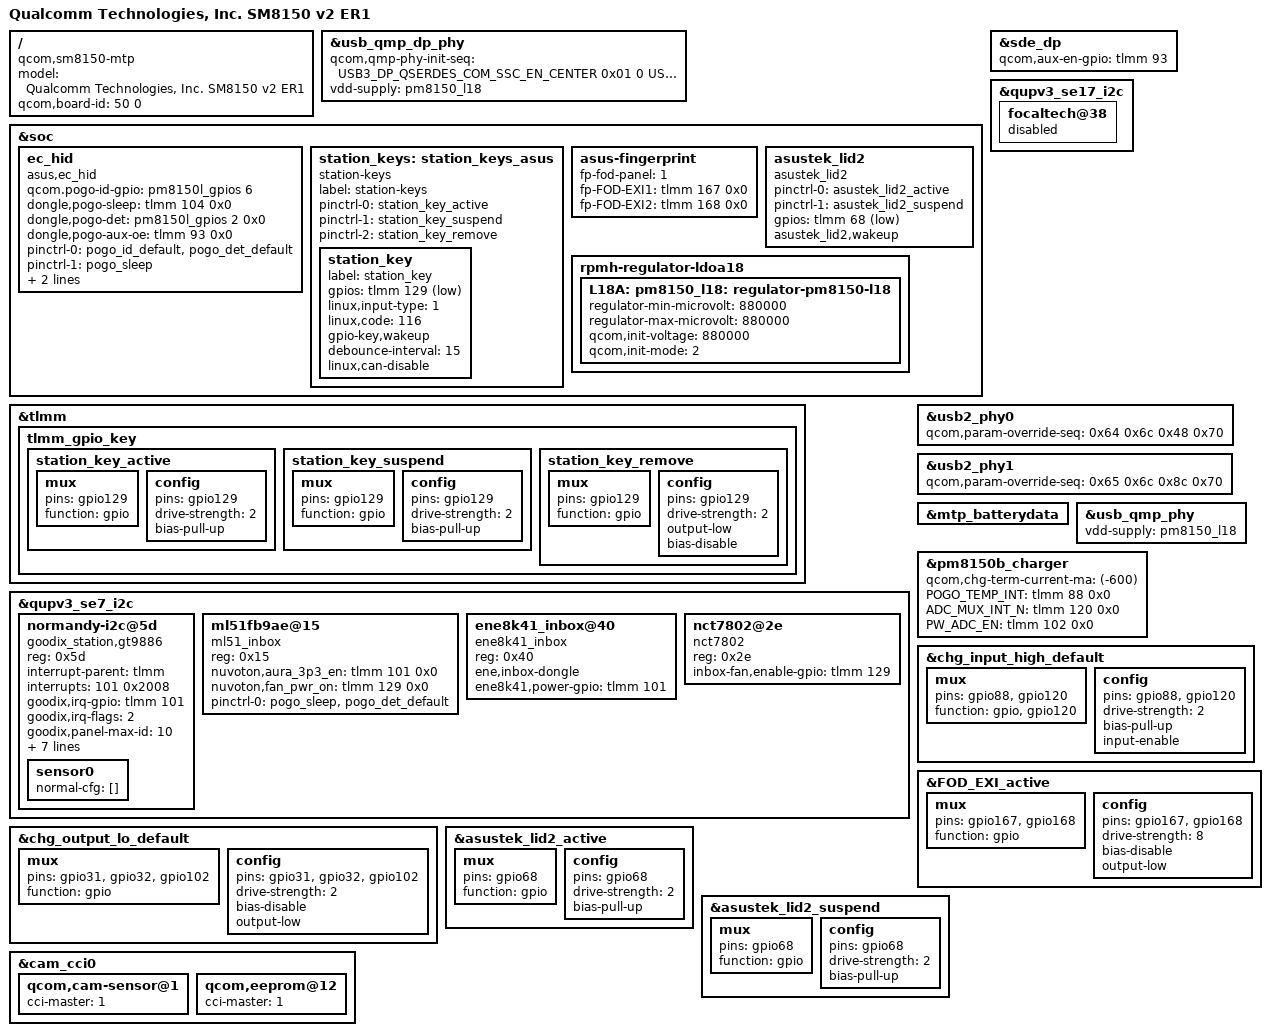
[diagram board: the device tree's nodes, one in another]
/* Copyright (c) 2017-2018, The Linux Foundation. All rights reserved.
 *
 * This program is free software; you can redistribute it and/or modify
 * it under the terms of the GNU General Public License version 2 and
 * only version 2 as published by the Free Software Foundation.
 *
 * This program is distributed in the hope that it will be useful,
 * but WITHOUT ANY WARRANTY; without even the implied warranty of
 * MERCHANTABILITY or FITNESS FOR A PARTICULAR PURPOSE.  See the
 * GNU General Public License for more details.
 */

/dts-v1/;
/plugin/;

#include "zs660kl-sr1-asus-overlay.dts"
#include <dt-bindings/phy/qcom,sm8150-qmp-usb3.h>

/ {
	model = "Qualcomm Technologies, Inc. SM8150 v2 ER1";
	compatible = "qcom,sm8150-mtp", "qcom,sm8150", "qcom,mtp";
	qcom,board-id = <50 0>;
};


/*    ====================================
 *    overlay for sm8150-v2.dtsi - start
 *    ====================================
 */

&usb_qmp_dp_phy {
	qcom,qmp-phy-init-seq =
	    <USB3_DP_QSERDES_COM_SSC_EN_CENTER 0x01 0
	     USB3_DP_QSERDES_COM_SSC_PER1 0x31 0
	     USB3_DP_QSERDES_COM_SSC_PER2 0x01 0
	     USB3_DP_QSERDES_COM_SSC_STEP_SIZE1_MODE0 0xde 0
	     USB3_DP_QSERDES_COM_SSC_STEP_SIZE2_MODE0 0x07 0
	     USB3_DP_QSERDES_COM_SSC_STEP_SIZE1_MODE1 0xde 0
	     USB3_DP_QSERDES_COM_SSC_STEP_SIZE2_MODE1 0x07 0
	     USB3_DP_QSERDES_COM_SYSCLK_BUF_ENABLE 0x0a 0
	     USB3_DP_QSERDES_COM_CMN_IPTRIM 0x20 0
	     USB3_DP_QSERDES_COM_CP_CTRL_MODE0 0x06 0
	     USB3_DP_QSERDES_COM_CP_CTRL_MODE1 0x06 0
	     USB3_DP_QSERDES_COM_PLL_RCTRL_MODE0 0x16 0
	     USB3_DP_QSERDES_COM_PLL_RCTRL_MODE1 0x16 0
	     USB3_DP_QSERDES_COM_PLL_CCTRL_MODE0 0x36 0
	     USB3_DP_QSERDES_COM_PLL_CCTRL_MODE1 0x36 0
	     USB3_DP_QSERDES_COM_SYSCLK_EN_SEL 0x1a 0
	     USB3_DP_QSERDES_COM_LOCK_CMP_EN 0x04 0
	     USB3_DP_QSERDES_COM_LOCK_CMP1_MODE0 0x14 0
	     USB3_DP_QSERDES_COM_LOCK_CMP2_MODE0 0x34 0
	     USB3_DP_QSERDES_COM_LOCK_CMP1_MODE1 0x34 0
	     USB3_DP_QSERDES_COM_LOCK_CMP2_MODE1 0x82 0
	     USB3_DP_QSERDES_COM_DEC_START_MODE0 0x82 0
	     USB3_DP_QSERDES_COM_DEC_START_MODE1 0x82 0
	     USB3_DP_QSERDES_COM_DIV_FRAC_START1_MODE0 0xab 0
	     USB3_DP_QSERDES_COM_DIV_FRAC_START2_MODE0 0xea 0
	     USB3_DP_QSERDES_COM_DIV_FRAC_START3_MODE0 0x02 0
	     USB3_DP_QSERDES_COM_DIV_FRAC_START1_MODE1 0xab 0
	     USB3_DP_QSERDES_COM_DIV_FRAC_START2_MODE1 0xea 0
	     USB3_DP_QSERDES_COM_DIV_FRAC_START3_MODE1 0x02 0
	     USB3_DP_QSERDES_COM_VCO_TUNE_MAP 0x02 0
	     USB3_DP_QSERDES_COM_VCO_TUNE1_MODE0 0x24 0
	     USB3_DP_QSERDES_COM_VCO_TUNE1_MODE1 0x24 0
	     USB3_DP_QSERDES_COM_VCO_TUNE2_MODE1 0x02 0
	     USB3_DP_QSERDES_COM_HSCLK_SEL 0x01 0
	     USB3_DP_QSERDES_COM_CORECLK_DIV_MODE1 0x08 0
	     USB3_DP_QSERDES_COM_BIN_VCOCAL_CMP_CODE1_MODE0 0xca 0
	     USB3_DP_QSERDES_COM_BIN_VCOCAL_CMP_CODE2_MODE0 0x1e 0
	     USB3_DP_QSERDES_COM_BIN_VCOCAL_CMP_CODE1_MODE1 0xca 0
	     USB3_DP_QSERDES_COM_BIN_VCOCAL_CMP_CODE2_MODE1 0x1e 0
	     USB3_DP_QSERDES_COM_BIN_VCOCAL_HSCLK_SEL 0x11 0
	     USB3_DP_QSERDES_TXA_TX_DRV_LVL 0x3f 0
	     USB3_DP_QSERDES_TXA_LANE_MODE_1 0xd5 0
	     USB3_DP_QSERDES_TXA_RCV_DETECT_LVL_2 0x12 0
	     USB3_DP_QSERDES_TXA_RES_CODE_LANE_TX 0x00 0
	     USB3_DP_QSERDES_TXA_RES_CODE_LANE_RX 0x00 0
	     USB3_DP_QSERDES_TXA_RES_CODE_LANE_OFFSET_TX 0x16 0
	     USB3_DP_QSERDES_TXA_RES_CODE_LANE_OFFSET_RX 0x05 0
	     USB3_DP_QSERDES_TXA_PI_QEC_CTRL 0x20 0
             USB3_DP_QSERDES_TXA_PRE_EMPH 0x25 0
	     USB3_DP_QSERDES_RXA_UCDR_SO_GAIN 0x05 0
	     USB3_DP_QSERDES_RXA_UCDR_FASTLOCK_FO_GAIN 0x2f 0
	     USB3_DP_QSERDES_RXA_UCDR_SO_SATURATION_AND_ENABLE 0x7f 0
	     USB3_DP_QSERDES_RXA_UCDR_FASTLOCK_COUNT_LOW 0xff 0
	     USB3_DP_QSERDES_RXA_UCDR_FASTLOCK_COUNT_HIGH 0x0f 0
	     USB3_DP_QSERDES_RXA_UCDR_PI_CONTROLS 0x99 0
	     USB3_DP_QSERDES_RXA_UCDR_SB2_THRESH1 0x04 0
	     USB3_DP_QSERDES_RXA_UCDR_SB2_THRESH2 0x08 0
	     USB3_DP_QSERDES_RXA_UCDR_SB2_GAIN1 0x05 0
	     USB3_DP_QSERDES_RXA_UCDR_SB2_GAIN2 0x05 0
	     USB3_DP_QSERDES_RXA_AUX_DATA_TCOARSE_TFINE 0xa0 0
	     USB3_DP_QSERDES_RXA_VGA_CAL_CNTRL1 0x54 0
	     USB3_DP_QSERDES_RXA_VGA_CAL_CNTRL2 0x0e 0
	     USB3_DP_QSERDES_RXA_GM_CAL 0x1f 0
	     USB3_DP_QSERDES_RXA_RX_EQU_ADAPTOR_CNTRL2 0x0f 0
	     USB3_DP_QSERDES_RXA_RX_EQU_ADAPTOR_CNTRL3 0x4a 0
	     USB3_DP_QSERDES_RXA_RX_EQU_ADAPTOR_CNTRL4 0x08 0
	     USB3_DP_QSERDES_RXA_RX_IDAC_TSETTLE_LOW 0xc0 0
	     USB3_DP_QSERDES_RXA_RX_IDAC_TSETTLE_HIGH 0x00 0
	     USB3_DP_QSERDES_RXA_RX_EQ_OFFSET_ADAPTOR_CNTRL1 0x77 0
	     USB3_DP_QSERDES_RXA_SIGDET_CNTRL 0x04 0
	     USB3_DP_QSERDES_RXA_SIGDET_DEGLITCH_CNTRL 0x0e 0
	     USB3_DP_QSERDES_RXA_RX_MODE_00_LOW 0xbf 0
	     USB3_DP_QSERDES_RXA_RX_MODE_00_HIGH 0xbf 0
	     USB3_DP_QSERDES_RXA_RX_MODE_00_HIGH2 0x3f 0
	     USB3_DP_QSERDES_RXA_RX_MODE_00_HIGH3 0x7f 0
	     USB3_DP_QSERDES_RXA_RX_MODE_00_HIGH4 0x94 0
	     USB3_DP_QSERDES_RXA_RX_MODE_01_LOW 0xdc 0
	     USB3_DP_QSERDES_RXA_RX_MODE_01_HIGH 0xdc 0
	     USB3_DP_QSERDES_RXA_RX_MODE_01_HIGH2 0x5c 0
	     USB3_DP_QSERDES_RXA_RX_MODE_01_HIGH3 0x0b 0
	     USB3_DP_QSERDES_RXA_RX_MODE_01_HIGH4 0xb3 0
	     USB3_DP_QSERDES_RXA_DFE_EN_TIMER 0x04 0
	     USB3_DP_QSERDES_RXA_DFE_CTLE_POST_CAL_OFFSET 0x38 0
	     USB3_DP_QSERDES_RXA_DCC_CTRL1 0xc 0
	     USB3_DP_QSERDES_RXA_VTH_CODE 0x10 0
	     USB3_DP_QSERDES_TXB_TX_DRV_LVL 0x3f 0
	     USB3_DP_QSERDES_TXB_LANE_MODE_1 0xd5 0
	     USB3_DP_QSERDES_TXB_RCV_DETECT_LVL_2 0x12 0
	     USB3_DP_QSERDES_TXB_RES_CODE_LANE_TX 0x00 0
	     USB3_DP_QSERDES_TXB_RES_CODE_LANE_RX 0x00 0
	     USB3_DP_QSERDES_TXB_RES_CODE_LANE_OFFSET_TX 0x16 0
	     USB3_DP_QSERDES_TXB_RES_CODE_LANE_OFFSET_RX 0x05 0
	     USB3_DP_QSERDES_TXB_PI_QEC_CTRL 0x01 0
	     USB3_DP_QSERDES_TXB_PRE_EMPH 0x25 0
	     USB3_DP_QSERDES_RXB_UCDR_SO_GAIN 0x05 0
	     USB3_DP_QSERDES_RXB_UCDR_FASTLOCK_FO_GAIN 0x2f 0
	     USB3_DP_QSERDES_RXB_UCDR_SO_SATURATION_AND_ENABLE 0x7f 0
	     USB3_DP_QSERDES_RXB_UCDR_FASTLOCK_COUNT_LOW 0xff 0
	     USB3_DP_QSERDES_RXB_UCDR_FASTLOCK_COUNT_HIGH 0x0f 0
	     USB3_DP_QSERDES_RXB_UCDR_PI_CONTROLS 0x99 0
	     USB3_DP_QSERDES_RXB_UCDR_SB2_THRESH1 0x04 0
	     USB3_DP_QSERDES_RXB_UCDR_SB2_THRESH2 0x08 0
	     USB3_DP_QSERDES_RXB_UCDR_SB2_GAIN1 0x05 0
	     USB3_DP_QSERDES_RXB_UCDR_SB2_GAIN2 0x05 0
	     USB3_DP_QSERDES_RXB_AUX_DATA_TCOARSE_TFINE 0xa0 0
	     USB3_DP_QSERDES_RXB_VGA_CAL_CNTRL1 0x54 0
	     USB3_DP_QSERDES_RXB_VGA_CAL_CNTRL2 0x0e 0
	     USB3_DP_QSERDES_RXB_GM_CAL 0x1f 0
	     USB3_DP_QSERDES_RXB_RX_EQU_ADAPTOR_CNTRL2 0x0f 0
	     USB3_DP_QSERDES_RXB_RX_EQU_ADAPTOR_CNTRL3 0x4a 0
	     USB3_DP_QSERDES_RXB_RX_EQU_ADAPTOR_CNTRL4 0x08 0
	     USB3_DP_QSERDES_RXB_RX_IDAC_TSETTLE_LOW 0xc0 0
	     USB3_DP_QSERDES_RXB_RX_IDAC_TSETTLE_HIGH 0x00 0
	     USB3_DP_QSERDES_RXB_RX_EQ_OFFSET_ADAPTOR_CNTRL1 0x77 0
	     USB3_DP_QSERDES_RXB_SIGDET_CNTRL 0x04 0
	     USB3_DP_QSERDES_RXB_SIGDET_DEGLITCH_CNTRL 0x0e 0
	     USB3_DP_QSERDES_RXB_RX_MODE_00_LOW 0xbf 0
	     USB3_DP_QSERDES_RXB_RX_MODE_00_HIGH 0xbf 0
	     USB3_DP_QSERDES_RXB_RX_MODE_00_HIGH2 0x3f 0
	     USB3_DP_QSERDES_RXB_RX_MODE_00_HIGH3 0x7f 0
	     USB3_DP_QSERDES_RXB_RX_MODE_00_HIGH4 0x94 0
	     USB3_DP_QSERDES_RXB_RX_MODE_01_LOW 0xdc 0
	     USB3_DP_QSERDES_RXB_RX_MODE_01_HIGH 0xdc 0
	     USB3_DP_QSERDES_RXB_RX_MODE_01_HIGH2 0x5c 0
	     USB3_DP_QSERDES_RXB_RX_MODE_01_HIGH3 0x0b 0
	     USB3_DP_QSERDES_RXB_RX_MODE_01_HIGH4 0xb3 0
	     USB3_DP_QSERDES_RXB_DFE_EN_TIMER 0x04 0
	     USB3_DP_QSERDES_RXB_DFE_CTLE_POST_CAL_OFFSET 0x38 0
	     USB3_DP_QSERDES_RXB_DCC_CTRL1 0xc 0
	     USB3_DP_QSERDES_RXB_VTH_CODE 0x10 0
	     USB3_DP_PCS_LOCK_DETECT_CONFIG1 0xd0 0
	     USB3_DP_PCS_LOCK_DETECT_CONFIG2 0x07 0
	     USB3_DP_PCS_LOCK_DETECT_CONFIG3 0x20 0
	     USB3_DP_PCS_LOCK_DETECT_CONFIG6 0x13 0
	     USB3_DP_PCS_REFGEN_REQ_CONFIG1 0x21 0
	     USB3_DP_PCS_RX_SIGDET_LVL 0xaa 0
	     USB3_DP_PCS_CDR_RESET_TIME 0x0f 0
	     USB3_DP_PCS_ALIGN_DETECT_CONFIG1 0x88 0
	     USB3_DP_PCS_ALIGN_DETECT_CONFIG2 0x13 0
	     USB3_DP_PCS_PCS_TX_RX_CONFIG 0x0c 0
	     USB3_DP_PCS_EQ_CONFIG1 0x4b 0
	     USB3_DP_PCS_EQ_CONFIG5 0x10 0
	     USB3_DP_PCS_USB3_LFPS_DET_HIGH_COUNT_VAL 0xf8 0
	     USB3_DP_PCS_USB3_RXEQTRAINING_DFE_TIME_S2 0x07 0
	     0xffffffff 0xffffffff 0x00>;
};

/*    ====================================
 *    overlay for sm8150-v2.dtsi - end
 *    ====================================
 */



/*    ====================================
 *    overlay for sm8150.dtsi - start
 *    ====================================
 */

// BSP SZ +++ Lotta_Lu EC_Driver
&soc {
	ec_hid {
		compatible = "asus,ec_hid";

		qcom.pogo-id-gpio = <&pm8150l_gpios 6 0x0>;
		dongle,pogo-sleep = <&tlmm 104 0x0>;
		dongle,pogo-det = <&pm8150l_gpios 2 0x0>;
		dongle,pogo-aux-oe = <&tlmm 93 0x0>;
		pinctrl-names = "default" , "pogo_sleep";
		pinctrl-0 = <&pogo_id_default &pogo_det_default >;
		pinctrl-1 = <&pogo_sleep>;

		io-channels = <&pm8150l_vadc ADC_GPIO2>;
		io-channel-names ="asus_pogo_vadc";
		qcom,pogo-id-adc_tm = <&pm8150l_adc_tm ADC_GPIO2>;
	};
};
// BSP SZ ---Lotta_Lu EC_Driver

// BSP SZ +++ Lotta_Lu Station Power Key
&soc {
	station_keys: station_keys_asus {
		compatible = "station-keys";
		label = "station-keys";

		pinctrl-names = "station_key_active","station_key_suspend","station_key_remove";
		pinctrl-0 = <&station_key_active>;
		pinctrl-1 = <&station_key_suspend>;
		pinctrl-2 = <&station_key_remove>;

		station_key {
			label = "station_key";
			gpios = <&tlmm 129 GPIO_ACTIVE_LOW>;
			linux,input-type = <1>;
			linux,code = <116>;
			gpio-key,wakeup;
			debounce-interval = <15>;
			linux,can-disable;
		};

	};

};

&tlmm{
	tlmm_gpio_key {
		station_key_active: station_key_active {
			mux {
				pins = "gpio129";
				function = "gpio";
			};

			config {
				pins = "gpio129";
				drive-strength = <2>;
				bias-pull-up;
			};
		};

		station_key_suspend: station_key_suspend {
			mux {
				pins = "gpio129";
				function = "gpio";
			};

			config {
				pins = "gpio129";
				drive-strength = <2>;
				bias-pull-up;
			};
		};

		station_key_remove: station_key_remove {
			mux {
				pins = "gpio129";
				function = "gpio";
			};

			config {
				pins = "gpio129";
				drive-strength = <2>;
				output-low;
				bias-disable;
			};
		};
	};
};
// BSP SZ --- Lotta_Lu Station Power Key

&soc {

// ASUS_BSP +++ Jacob Fingerprint sensor
	asus-fingerprint {
		fp-fod-panel = <1>;
		fp-FOD-EXI1 = <&tlmm 167 0x0>;
		fp-FOD-EXI2 = <&tlmm 168 0x0>;
	};
// ASUS_BSP --- Jacob Fingerprint sensor

};

//ASUS_BSP Deeo : hall sensor for bumper +++
&soc {
	/* hall sensor for Bumper */
	asustek_lid2 {
		status = "ok";
		compatible = "asustek_lid2";
		pinctrl-names = "asustek_lid2_active", "asustek_lid2_suspend";
		pinctrl-0 = <&asustek_lid2_active>;
		pinctrl-1 = <&asustek_lid2_suspend>;
		gpios = <&tlmm 68 0x1>;
		asustek_lid2,wakeup;
	};
};
//ASUS_BSP Deeo : hall sensor for bumper ---

// BSP SZ +++ Lydia_Wu add for DisplayPort
&sde_dp {
	qcom,aux-en-gpio = <&tlmm 93 0>;
};
// BSP SZ --- Lydia_Wu add for DisplayPort

/*    ====================================
 *    overlay for sm8150-v2.dtsi/sm8150.dtsi - end
 *    ====================================
 */



/*    ====================================
 *    overlay for sm8150-mtp.dtsi - start
 *    ====================================
 */

// ASUS_SZ_BSP Yadong : Add station goodix touch +++
&qupv3_se7_i2c {
	status = "ok";
	normandy-i2c@5d{
		compatible = "goodix_station,gt9886";
		reg = <0x5d>;
		interrupt-parent = <&tlmm>;
		interrupts = <101 0x2008>;
		//pinctrl-names = "pmx_ts_active","pmx_ts_suspend";
		//pinctrl-0 = <&ts_int_active &ts_reset_active>;
		//pinctrl-1 = <&ts_int_suspend &ts_reset_suspend>;
		goodix,irq-gpio = <&tlmm 101 0x2008>;
		goodix,irq-flags = <2>; /* 1:trigger rising, 2:trigger falling;*/
		goodix,panel-max-id = <10>; //max touch numbers
		goodix,panel-max-x = <1080>; // x
		goodix,panel-max-y = <2340>; // y
		goodix,panel-max-w = <512>; //touch major
		goodix,panel-max-p = <512>; //touch pressure
		goodix,panel-key-map = <158 172 217>; /*KEY_BACK, KEY_HOMEPAGE, KEY_SEARCH*/
		goodix,power-on-delay-us = <300000>; /*300ms*/
		goodix,power-off-delay-us = <5000>;
		/*goodix,swap-axis;
		goodix,x2x;
		goodix,y2y;
		goodix,pen-enable;
		goodix,key-of-pen = <331 332>;*//*BTN_STYLUS, BTN_STYLUS2*/
		sensor0 {
		    normal-cfg = [];
		};
	};
};

&qupv3_se17_i2c {
	focaltech@38 {
		status = "disable";
	};
};
// ASUS_SZ_BSP Yadong : Add station goodix touch ---

// ASUS_SZ_BSP Cassie : Inbox AURA ML51 +++
&qupv3_se7_i2c {
       status = "ok";
       ml51fb9ae@15 {
               compatible = "ml51_inbox";
               reg = <0x15>;

               //nuvoton,pogo-sleep = <&tlmm 104 0x0>;
               //nuvoton,pogo-det = <&pm8150l_gpios 2 0x0>;

               nuvoton,aura_3p3_en = <&tlmm 101 0x0>;
               nuvoton,fan_pwr_on = <&tlmm 129 0x0>;


               pinctrl-names = "pogo_sleep";
               pinctrl-0 = <&pogo_sleep &pogo_det_default>;
       };
};
// ASUS_SZ_BSP Cassie : Inbox AURA ML51 ---

//ASUS_SZ_BSP Cassie : Aura sync on dt and jedi's inbox +++
&qupv3_se7_i2c {
    status = "ok";
    ene8k41_inbox@40 {
        compatible = "ene8k41_inbox";
        reg = <0x40>;
        ene,inbox-dongle;
        ene8k41,power-gpio =<&tlmm 101 0x0>;

    };
};
//ASUS_SZ_BSP Cassie : Aura sync on dt and jedi's inbox ---

//ASUS_SZ_BSP Cassie : FAN +++
&qupv3_se7_i2c {
    status = "ok";
    nct7802@2e {
       reg = <0x2e>;
        compatible = "nct7802";
        inbox-fan,enable-gpio = <&tlmm 129 0x0>;
        pinctrl-names = "fan_enable";
    };

};
//ASUS_SZ_BSP Cassie : FAN  ---


&usb2_phy0 {
	qcom,param-override-seq =
		<0x64 0x6c
		 0x48 0x70>;
};
 
&usb2_phy1 {
	qcom,param-override-seq =
		<0x65 0x6c
		 0x8c 0x70>;
};

/*    ====================================
 *    overlay for sm8150-mtp.dtsi - end
 *    ====================================
 */

//ASUS BSP Charger +++
&mtp_batterydata {
	#include "fg-gen4-batterydata-5800mah_4p35V.dtsi"
};
//ASUS BSP Charger ---

/*    ====================================
 *    overlay for pmi8998.dtsi/pm8998.dtsi - start
 *    ====================================
 */

&usb_qmp_dp_phy {
	vdd-supply = <&pm8150_l18>;
};

&usb_qmp_phy {
	vdd-supply = <&pm8150_l18>;
};
 
&soc {
	rpmh-regulator-ldoa18 {
		L18A: pm8150_l18: regulator-pm8150-l18 {
			regulator-min-microvolt = <880000>;
			regulator-max-microvolt = <880000>;
			qcom,init-voltage = <880000>;
			qcom,init-mode = <2>;	/*RPMH_REGULATOR_MODE_LPM*/
		};
	};
};

//ASUS BSP Charger +++
&pm8150b_charger {
	qcom,chg-term-current-ma = <(-600)>;

	POGO_TEMP_INT = <&tlmm 88 0x0>;
	ADC_MUX_INT_N = <&tlmm 120 0x0>;
	PW_ADC_EN = <&tlmm 102 0x0>;
};
//ASUS BSP Charger ---

/*    ====================================
 *    overlay for pmi8998.dtsi/pm8998.dtsi - end
 *    ====================================
 */



/*    ====================================
 *    overlay for sm8150-pinctrl.dtsi - start
 *    ====================================
 */

//ASUS BSP Charger +++
&chg_output_lo_default {
	mux {
		pins = "gpio31", "gpio32", "gpio102";
		function = "gpio";
	};

	config {
		pins = "gpio31", "gpio32", "gpio102";
		drive-strength = <2>;
		bias-disable;
		output-low;
	};
};

&chg_input_high_default {
	mux {
		pins = "gpio88", "gpio120";
		function = "gpio", "gpio120";
	};

	config {
		pins = "gpio88", "gpio120";
		drive-strength = <2>;
		bias-pull-up;
		input-enable;
	};
};
//ASUS BSP Charger ---

&FOD_EXI_active {
	mux {
		pins = "gpio167", "gpio168";
		function = "gpio";
	};
	config {
		pins = "gpio167", "gpio168";
		drive-strength = <8>;   /* 8 mA */
		bias-disable;           /* NO PULL */
		output-low;
	};
};

//ASUS_BSP Deeo : hall sensor for bumper +++
&asustek_lid2_active {
				mux {
					pins = "gpio68";
					function = "gpio";
				};

				config {
					pins = "gpio68";
					drive-strength = <2>;
					bias-pull-up;
				};
};

&asustek_lid2_suspend {
				mux {
					pins = "gpio68";
					function = "gpio";
				};

				config {
					pins = "gpio68";
					drive-strength = <2>;
					bias-pull-up;
				};
};
//ASUS_BSP Deeo : hall sensor for bumper ---

/*    ====================================
 *    overlay for sm8150-pinctrl.dtsi - end
 *    ====================================
 */


/*    ====================================
 *    overlay for sm8150-pmic.dtsi - start
 *    ====================================
 */

/*    ====================================
 *    overlay for sm8150-pmic.dtsi - end
 *    ====================================
 */



/*    ====================================
 *    overlay for sm8150-regulator.dtsi - start
 *    ====================================
 */

/*    ====================================
 *    overlay for sm8150-regulator.dtsi - end
 *    ====================================
 */
  

 
/*    ====================================
 *    overlay for sm8150-v2-camera.dtsi - start
 *    ====================================
 */
 //ASUS_BSP Ryan : camera +++
&cam_cci0 {
  qcom,cam-sensor@1 {
    cci-master = <1>;
  };
    qcom,eeprom@12 {
  	cci-master = <1>;
  };
};
 //ASUS_BSP Ryan : camera ---
/*    ====================================
 *    overlay for sm8150-v2-camera.dtsi - end
 *    ====================================
 */



/*    ====================================
 *    overlay for sm8150-camera-sensor-mtp.dtsi - start
 *    ====================================
 */

/*    ====================================
 *    overlay for sm8150-camera-sensor-mtp.dtsi - end
 *    ====================================
 */
 


/*    ====================================
 *    overlay for sm8150-camera.dtsi - start
 *    ====================================
 */

/*    ====================================
 *    overlay for sm8150-camera.dtsi - end
 *    ====================================
 */



